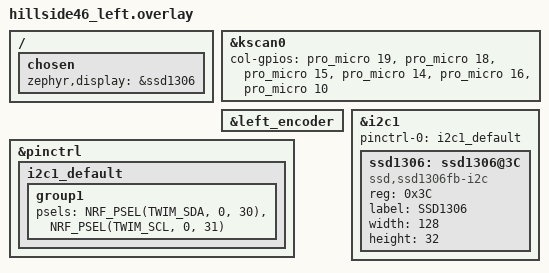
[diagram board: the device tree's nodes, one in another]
/*
 * Copyright (c) 2021-2022 The ZMK Contributors
 *
 * SPDX-License-Identifier: MIT
 */

#include "hillside46.dtsi"

// Tangentbordskonfiguration för kscan
&kscan0 {
    col-gpios = <&pro_micro 19 GPIO_ACTIVE_HIGH> // col0 in the schematic
               , <&pro_micro 18 GPIO_ACTIVE_HIGH> // col1 in the schematic
               , <&pro_micro 15 GPIO_ACTIVE_HIGH> // col2 in the schematic
               , <&pro_micro 14 GPIO_ACTIVE_HIGH> // col3 in the schematic
               , <&pro_micro 16 GPIO_ACTIVE_HIGH> // col4 in the schematic
               , <&pro_micro 10 GPIO_ACTIVE_HIGH> // col5 in the schematic
               ;
};

// Konfiguration för din vänstra encoder
&left_encoder {
    status = "okay";
};

// I²C pinctrl configuration
&pinctrl {
    i2c1_default: i2c1_default {
        group1 {
            psels = <NRF_PSEL(TWIM_SDA, 0, 30)>,
                    <NRF_PSEL(TWIM_SCL, 0, 31)>;
        };
    };
};

// I²C och OLED-konfiguration
&i2c1 {
    status = "okay";
    pinctrl-0 = <&i2c1_default>;
    pinctrl-names = "default";
    
    ssd1306: ssd1306@3C {
        compatible = "ssd,ssd1306fb-i2c";
        reg = <0x3C>;
        label = "SSD1306";
        width = <128>;
        height = <32>;
    };
};

/ {
    chosen {
        zephyr,display = &ssd1306;
    };
};
